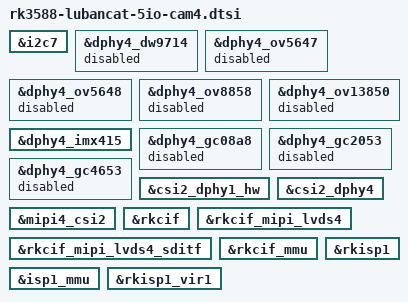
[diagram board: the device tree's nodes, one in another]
&i2c7 {
	status = "okay";
};

&dphy4_dw9714 {
	status = "disabled";
};

&dphy4_ov5647 {
	status = "disabled";
};

&dphy4_ov5648 {
	status = "disabled";
};

&dphy4_ov8858 {
	status = "disabled";
};

&dphy4_ov13850 {
	status = "disabled";
};

&dphy4_imx415 {
	status = "okay";
};

&dphy4_gc08a8 {
	status = "disabled";
};

&dphy4_gc2053 {
	status = "disabled";
};

&dphy4_gc4653 {
	status = "disabled";
};

&csi2_dphy1_hw {
	status = "okay";
};

&csi2_dphy4 {
	status = "okay";
};

&mipi4_csi2 {
	status = "okay";
};

&rkcif {
	status = "okay";
};

&rkcif_mipi_lvds4 {
	status = "okay";
};

&rkcif_mipi_lvds4_sditf {
	status = "okay";
};

&rkcif_mmu {
	status = "okay";
};

&rkisp1 {
	status = "okay";
};

&isp1_mmu {
	status = "okay";
};

&rkisp1_vir1 {
	status = "okay";
};
